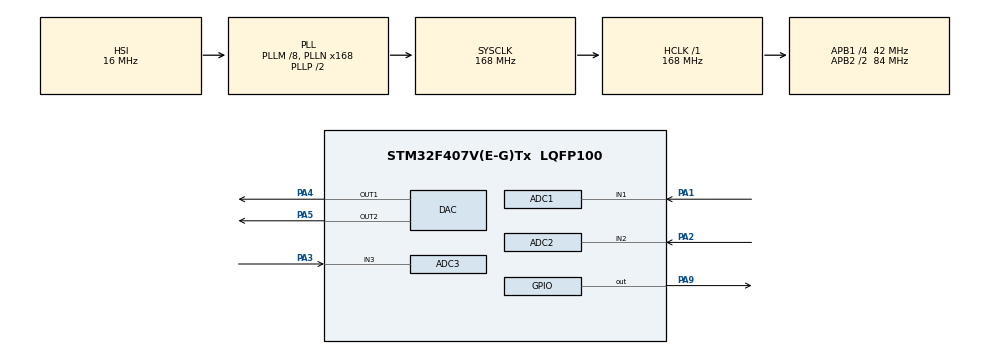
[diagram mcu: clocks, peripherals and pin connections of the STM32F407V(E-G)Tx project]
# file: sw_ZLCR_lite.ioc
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ADC1.AutoInjectedConv=DISABLE
ADC1.Channel-0\#ChannelRegularConversion=ADC_CHANNEL_1
ADC1.ClockPrescaler=ADC_CLOCK_SYNC_PCLK_DIV4
ADC1.ContinuousConvMode=DISABLE
ADC1.DMAAccessMode=ADC_DMAACCESSMODE_1
ADC1.DMAContinuousRequests=ENABLE
ADC1.DataAlign=ADC_DATAALIGN_RIGHT
ADC1.DiscontinuousConvMode=DISABLE
ADC1.EOCSelection=ADC_EOC_SEQ_CONV
ADC1.EnableAnalogWatchDog=false
ADC1.ExternalTrigConv=ADC_EXTERNALTRIGCONV_T2_TRGO
ADC1.ExternalTrigConvEdge=ADC_EXTERNALTRIGCONVEDGE_RISING
ADC1.InjNumberOfConversion=0
ADC1.InjectedDiscontinuousConvMode=DISABLE
ADC1.Mode=ADC_TRIPLEMODE_REGSIMULT
ADC1.NbrOfConversion=1
ADC1.NbrOfConversionFlag=1
ADC1.Rank-0\#ChannelRegularConversion=1
ADC1.Resolution=ADC_RESOLUTION_12B
ADC1.SamplingTime-0\#ChannelRegularConversion=ADC_SAMPLETIME_3CYCLES
ADC1.ScanConvMode=DISABLE
ADC1.master=1
ADC2.AutoInjectedConv=DISABLE
ADC2.Channel-0\#ChannelRegularConversion=ADC_CHANNEL_2
ADC2.ClockPrescaler=ADC_CLOCK_SYNC_PCLK_DIV4
ADC2.ContinuousConvMode=DISABLE
ADC2.DMAAccessMode=ADC_DMAACCESSMODE_1
ADC2.DMAContinuousRequests=DISABLE
ADC2.DataAlign=ADC_DATAALIGN_RIGHT
ADC2.DiscontinuousConvMode=DISABLE
ADC2.EOCSelection=ADC_EOC_SINGLE_CONV
ADC2.EnableAnalogWatchDog=false
ADC2.InjectedDiscontinuousConvMode=DISABLE
ADC2.Mode=ADC_TRIPLEMODE_REGSIMULT
ADC2.NbrOfConversion=1
ADC2.NbrOfConversionFlag=1
ADC2.Rank-0\#ChannelRegularConversion=1
ADC2.Resolution=ADC_RESOLUTION_12B
ADC2.SamplingTime-0\#ChannelRegularConversion=ADC_SAMPLETIME_3CYCLES
ADC2.ScanConvMode=DISABLE
ADC3.AutoInjectedConv=DISABLE
ADC3.Channel-0\#ChannelRegularConversion=ADC_CHANNEL_3
ADC3.DMAAccessMode=ADC_DMAACCESSMODE_1
ADC3.InjectedDiscontinuousConvMode=DISABLE
ADC3.Mode=ADC_TRIPLEMODE_REGSIMULT
ADC3.NbrOfConversionFlag=1
ADC3.Rank-0\#ChannelRegularConversion=1
ADC3.SamplingTime-0\#ChannelRegularConversion=ADC_SAMPLETIME_3CYCLES
DAC.DAC_Channel=DAC_CHANNEL_1
DAC.DAC_Channel2=DAC_CHANNEL_2
DAC.DAC_Trigger=DAC_TRIGGER_T2_TRGO
DAC.DAC_Trigger2=DAC_TRIGGER_SOFTWARE
DAC.WaveGeneration=DISABLE
DAC.WaveGeneration2=DISABLE
Dma.ADC1.0.Direction=DMA_PERIPH_TO_MEMORY
Dma.ADC1.0.FIFOMode=DMA_FIFOMODE_DISABLE
Dma.ADC1.0.Instance=DMA2_Stream0
Dma.ADC1.0.MemDataAlignment=DMA_MDATAALIGN_HALFWORD
Dma.ADC1.0.MemInc=DMA_MINC_ENABLE
Dma.ADC1.0.Mode=DMA_CIRCULAR
Dma.ADC1.0.PeriphDataAlignment=DMA_PDATAALIGN_HALFWORD
Dma.ADC1.0.PeriphInc=DMA_PINC_DISABLE
Dma.ADC1.0.Priority=DMA_PRIORITY_LOW
Dma.DAC1.1.Direction=DMA_MEMORY_TO_PERIPH
Dma.DAC1.1.FIFOMode=DMA_FIFOMODE_DISABLE
Dma.DAC1.1.Instance=DMA1_Stream5
Dma.DAC1.1.MemDataAlignment=DMA_MDATAALIGN_HALFWORD
Dma.DAC1.1.MemInc=DMA_MINC_ENABLE
Dma.DAC1.1.Mode=DMA_CIRCULAR
Dma.DAC1.1.PeriphDataAlignment=DMA_PDATAALIGN_HALFWORD
Dma.DAC1.1.PeriphInc=DMA_PINC_DISABLE
Dma.DAC1.1.Priority=DMA_PRIORITY_LOW
Dma.Request0=ADC1
Dma.Request1=DAC1
Mcu.Family=STM32F4
Mcu.Name=STM32F407V(E-G)Tx
Mcu.Package=LQFP100
NVIC.DMA1_Stream5_IRQn=true\:0\:0\:false\:false\:true
NVIC.DMA2_Stream0_IRQn=true\:0\:0\:false\:false\:true
NVIC.PriorityGroup=NVIC_PRIORITYGROUP_4
PA1.Signal=ADCx_IN1
PA13.Mode=Serial_Wire
PA13.Signal=SYS_JTMS-SWDIO
PA14.Mode=Serial_Wire
PA14.Signal=SYS_JTCK-SWCLK
PA2.Signal=ADCx_IN2
PA3.Signal=ADCx_IN3
PA4.Signal=COMP_DAC1_group
PA5.Signal=COMP_DAC2_group
PA9.Signal=GPIO_Output
PH0-OSC_IN.Mode=HSE-External-Clock-Source
PH0-OSC_IN.Signal=RCC_OSC_IN
PH1-OSC_OUT.Mode=HSE-External-Clock-Source
PH1-OSC_OUT.Signal=RCC_OSC_OUT
ProjectManager.HeapSize=0x1000
ProjectManager.StackSize=0x400
ProjectManager.TargetToolchain=MDK-ARM V5
RCC.48MHZClocksFreq_Value=84000000
RCC.AHBCLKDivider=RCC_SYSCLK_DIV1
RCC.AHBFreq_Value=168000000
RCC.APB1CLKDivider=RCC_HCLK_DIV4
RCC.APB1Freq_Value=42000000
RCC.APB1TimFreq_Value=84000000
RCC.APB2CLKDivider=RCC_HCLK_DIV2
RCC.APB2Freq_Value=84000000
RCC.APB2TimFreq_Value=168000000
RCC.ClockTypeHCLK=RCC_CLOCKTYPE_HCLK
RCC.ClockTypePCLK1=RCC_CLOCKTYPE_PCLK1
RCC.ClockTypePCLK2=RCC_CLOCKTYPE_PCLK2
RCC.ClockTypeSysClk=RCC_CLOCKTYPE_SYSCLK
RCC.CortexFreq_Value=168000000
RCC.Cortex_Div=SYSTICK_CLKSOURCE_HCLK
RCC.EnableExtClockForI2S=false
RCC.EnableHSE=true
RCC.EnableHSERTCDevisor=false
RCC.EnableLSE=false
RCC.EnableLSERTC=false
RCC.ExtClockEnable=false
RCC.HCLKFreq_Value=168000000
RCC.HSEState=RCC_HSE_BYPASS
RCC.HSE_VALUE=8000000
RCC.HSIState=RCC_HSI_ON
RCC.HSI_VALUE=16000000
RCC.I2SEnable=false
RCC.IWDGEnable=false
RCC.LSE_VALUE=32768
RCC.LSIState=RCC_LSI_OFF
RCC.MCO1OutPutEnable=false
RCC.MCO2OutPutEnable=false
RCC.OscillatorTypeHSI=RCC_OSCILLATORTYPE_HSI
RCC.PLLM=8
RCC.PLLN=168
RCC.PLLP=RCC_PLLP_DIV2
RCC.PLLSource=RCC_PLLSOURCE_HSI
RCC.PLLSourceVirtual=RCC_PLLSOURCE_HSI
RCC.PLLState=RCC_PLL_ON
RCC.RCC_MCODiv1=RCC_MCODIV_1
RCC.RCC_MCODiv2=RCC_MCODIV_1
RCC.RCC_RTC_Clock_Source_FROM_HSE=RCC_RTCCLKSOURCE_HSE_DIV2
RCC.RNGEnable=false
RCC.RTCEnable=false
RCC.SDIOEnable=false
RCC.SYSCLKFreq_VALUE=168000000
RCC.SYSCLKSource=RCC_SYSCLKSOURCE_PLLCLK
RCC.USBFSEnable=false
RCC.USBHSEnable=false
RCC.VCOOutputFreq_Value=336000000
SH.ADCx_IN1.0=ADC1_IN1,IN1
SH.ADCx_IN2.0=ADC2_IN2,IN2
SH.ADCx_IN3.0=ADC3_IN3,IN3
SH.COMP_DAC1_group.0=DAC_OUT1,DAC_OUT1
SH.COMP_DAC2_group.0=DAC_OUT2,DAC_OUT2
TIM2.Period=1679
TIM2.TIM_MasterOutputTrigger=TIM_TRGO_UPDATE
VP_TIM2_VS_ClockSourceINT.Mode=Internal
board=sw_ZLCR_lite

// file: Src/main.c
/**
  ******************************************************************************
  * File Name          : main.c
  * Description        : Main program body
  ******************************************************************************
  *
  * COPYRIGHT(c) 2017 STMicroelectronics
  *
  * Redistribution and use in source and binary forms, with or without modification,
  * are permitted provided that the following conditions are met:
  *   1. Redistributions of source code must retain the above copyright notice,
  *      this list of conditions and the following disclaimer.
  *   2. Redistributions in binary form must reproduce the above copyright notice,
  *      this list of conditions and the following disclaimer in the documentation
  *      and/or other materials provided with the distribution.
  *   3. Neither the name of STMicroelectronics nor the names of its contributors
  *      may be used to endorse or promote products derived from this software
  *      without specific prior written permission.
  *
  * THIS SOFTWARE IS PROVIDED BY THE COPYRIGHT HOLDERS AND CONTRIBUTORS "AS IS"
  * AND ANY EXPRESS OR IMPLIED WARRANTIES, INCLUDING, BUT NOT LIMITED TO, THE
  * IMPLIED WARRANTIES OF MERCHANTABILITY AND FITNESS FOR A PARTICULAR PURPOSE ARE
  * DISCLAIMED. IN NO EVENT SHALL THE COPYRIGHT HOLDER OR CONTRIBUTORS BE LIABLE
  * FOR ANY DIRECT, INDIRECT, INCIDENTAL, SPECIAL, EXEMPLARY, OR CONSEQUENTIAL
  * DAMAGES (INCLUDING, BUT NOT LIMITED TO, PROCUREMENT OF SUBSTITUTE GOODS OR
  * SERVICES; LOSS OF USE, DATA, OR PROFITS; OR BUSINESS INTERRUPTION) HOWEVER
  * CAUSED AND ON ANY THEORY OF LIABILITY, WHETHER IN CONTRACT, STRICT LIABILITY,
  * OR TORT (INCLUDING NEGLIGENCE OR OTHERWISE) ARISING IN ANY WAY OUT OF THE USE
  * OF THIS SOFTWARE, EVEN IF ADVISED OF THE POSSIBILITY OF SUCH DAMAGE.
  *
  ******************************************************************************
  */
#include "main.h"
#include "stm32f4xx_hal.h"

/* USER CODE BEGIN Includes */
#include "BSP.h"
/* USER CODE END Includes */

ADC_HandleTypeDef hadc1;
ADC_HandleTypeDef hadc2;
ADC_HandleTypeDef hadc3;
DMA_HandleTypeDef hdma_adc1;

DAC_HandleTypeDef hdac;
DMA_HandleTypeDef hdma_dac1;

TIM_HandleTypeDef htim2;

/* USER CODE BEGIN PV */
/* Private variables ---------------------------------------------------------*/

/* USER CODE END PV */

void SystemClock_Config(void);
void Error_Handler(void);
static void MX_GPIO_Init(void);
static void MX_DMA_Init(void);
static void MX_ADC1_Init(void);
static void MX_ADC2_Init(void);
static void MX_ADC3_Init(void);
static void MX_DAC_Init(void);
static void MX_TIM2_Init(void);

/* USER CODE BEGIN PFP */
/* Private function prototypes -----------------------------------------------*/

/* USER CODE END PFP */

/* USER CODE BEGIN 0 */
void HAL_ADC_ConvCpltCallback(ADC_HandleTypeDef* hadc)
{
    HAL_GPIO_TogglePin(GPIOA, GPIO_PIN_9);
}
/* USER CODE END 0 */

int main(void)
{

  /* MCU Configuration----------------------------------------------------------*/

  /* Reset of all peripherals, Initializes the Flash interface and the Systick. */
  HAL_Init();

  /* Configure the system clock */
  SystemClock_Config();

  /* Initialize all configured peripherals */
  MX_GPIO_Init();
  MX_DMA_Init();
  MX_ADC1_Init();
  MX_ADC2_Init();
  MX_ADC3_Init();
  MX_DAC_Init();
  MX_TIM2_Init();

  /* USER CODE BEGIN 2 */
    HAL_DAC_SetValue(&hdac, DAC1_CHANNEL_1, DAC_ALIGN_12B_R, 2047);
    HAL_DAC_Start_DMA(&hdac, DAC1_CHANNEL_1, (uint32_t *)I2S_DACBuf, 100, DAC_ALIGN_12B_R);
    HAL_DAC_Start(&hdac, DAC1_CHANNEL_2);
    HAL_ADCEx_MultiModeStart_DMA(&hadc1, (uint32_t *)&I2S_ADCBuf, 300);
    __HAL_ADC_ENABLE(&hadc1);
    __HAL_ADC_ENABLE(&hadc2);
    __HAL_ADC_ENABLE(&hadc3);
    HAL_TIM_Base_Start(&htim2);
  /* USER CODE END 2 */

  /* Infinite loop */
  while (1)
  {

  }

}

/** System Clock Configuration
*/
void SystemClock_Config(void)
{

  RCC_OscInitTypeDef RCC_OscInitStruct;
  RCC_ClkInitTypeDef RCC_ClkInitStruct;

    /**Configure the main internal regulator output voltage
    */
  __HAL_RCC_PWR_CLK_ENABLE();

  __HAL_PWR_VOLTAGESCALING_CONFIG(PWR_REGULATOR_VOLTAGE_SCALE1);

    /**Initializes the CPU, AHB and APB busses clocks
    */
  RCC_OscInitStruct.OscillatorType = RCC_OSCILLATORTYPE_HSI;
  RCC_OscInitStruct.HSIState = RCC_HSI_ON;
  RCC_OscInitStruct.HSICalibrationValue = 16;
  RCC_OscInitStruct.PLL.PLLState = RCC_PLL_ON;
  RCC_OscInitStruct.PLL.PLLSource = RCC_PLLSOURCE_HSI;
  RCC_OscInitStruct.PLL.PLLM = 8;
  RCC_OscInitStruct.PLL.PLLN = 168;
  RCC_OscInitStruct.PLL.PLLP = RCC_PLLP_DIV2;
  RCC_OscInitStruct.PLL.PLLQ = 4;
  if (HAL_RCC_OscConfig(&RCC_OscInitStruct) != HAL_OK)
  {
    Error_Handler();
  }

    /**Initializes the CPU, AHB and APB busses clocks
    */
  RCC_ClkInitStruct.ClockType = RCC_CLOCKTYPE_HCLK|RCC_CLOCKTYPE_SYSCLK
                              |RCC_CLOCKTYPE_PCLK1|RCC_CLOCKTYPE_PCLK2;
  RCC_ClkInitStruct.SYSCLKSource = RCC_SYSCLKSOURCE_PLLCLK;
  RCC_ClkInitStruct.AHBCLKDivider = RCC_SYSCLK_DIV1;
  RCC_ClkInitStruct.APB1CLKDivider = RCC_HCLK_DIV4;
  RCC_ClkInitStruct.APB2CLKDivider = RCC_HCLK_DIV2;

  if (HAL_RCC_ClockConfig(&RCC_ClkInitStruct, FLASH_LATENCY_5) != HAL_OK)
  {
    Error_Handler();
  }

    /**Configure the Systick interrupt time
    */
  HAL_SYSTICK_Config(HAL_RCC_GetHCLKFreq()/1000);

    /**Configure the Systick
    */
  HAL_SYSTICK_CLKSourceConfig(SYSTICK_CLKSOURCE_HCLK);

  /* SysTick_IRQn interrupt configuration */
  HAL_NVIC_SetPriority(SysTick_IRQn, 0, 0);
}

/* ADC1 init function */
static void MX_ADC1_Init(void)
{

  ADC_MultiModeTypeDef multimode;
  ADC_ChannelConfTypeDef sConfig;

    /**Configure the global features of the ADC (Clock, Resolution, Data Alignment and number of conversion)
    */
  hadc1.Instance = ADC1;
  hadc1.Init.ClockPrescaler = ADC_CLOCK_SYNC_PCLK_DIV4;
  hadc1.Init.Resolution = ADC_RESOLUTION_12B;
  hadc1.Init.ScanConvMode = DISABLE;
  hadc1.Init.ContinuousConvMode = DISABLE;
  hadc1.Init.DiscontinuousConvMode = DISABLE;
  hadc1.Init.ExternalTrigConvEdge = ADC_EXTERNALTRIGCONVEDGE_RISING;
  hadc1.Init.ExternalTrigConv = ADC_EXTERNALTRIGCONV_T2_TRGO;
  hadc1.Init.DataAlign = ADC_DATAALIGN_RIGHT;
  hadc1.Init.NbrOfConversion = 1;
  hadc1.Init.DMAContinuousRequests = ENABLE;
  hadc1.Init.EOCSelection = ADC_EOC_SEQ_CONV;
  if (HAL_ADC_Init(&hadc1) != HAL_OK)
  {
    Error_Handler();
  }

    /**Configure the ADC multi-mode
    */
  multimode.Mode = ADC_TRIPLEMODE_REGSIMULT;
  multimode.DMAAccessMode = ADC_DMAACCESSMODE_1;
  multimode.TwoSamplingDelay = ADC_TWOSAMPLINGDELAY_5CYCLES;
  if (HAL_ADCEx_MultiModeConfigChannel(&hadc1, &multimode) != HAL_OK)
  {
    Error_Handler();
  }

    /**Configure for the selected ADC regular channel its corresponding rank in the sequencer and its sample time.
    */
  sConfig.Channel = ADC_CHANNEL_1;
  sConfig.Rank = 1;
  sConfig.SamplingTime = ADC_SAMPLETIME_3CYCLES;
  if (HAL_ADC_ConfigChannel(&hadc1, &sConfig) != HAL_OK)
  {
    Error_Handler();
  }

}

/* ADC2 init function */
static void MX_ADC2_Init(void)
{

  ADC_ChannelConfTypeDef sConfig;

    /**Configure the global features of the ADC (Clock, Resolution, Data Alignment and number of conversion)
    */
  hadc2.Instance = ADC2;
  hadc2.Init.ClockPrescaler = ADC_CLOCK_SYNC_PCLK_DIV4;
  hadc2.Init.Resolution = ADC_RESOLUTION_12B;
  hadc2.Init.ScanConvMode = DISABLE;
  hadc2.Init.ContinuousConvMode = DISABLE;
  hadc2.Init.DiscontinuousConvMode = DISABLE;
  hadc2.Init.DataAlign = ADC_DATAALIGN_RIGHT;
  hadc2.Init.NbrOfConversion = 1;
  hadc2.Init.DMAContinuousRequests = DISABLE;
  hadc2.Init.EOCSelection = ADC_EOC_SINGLE_CONV;
  if (HAL_ADC_Init(&hadc2) != HAL_OK)
  {
    Error_Handler();
  }

    /**Configure for the selected ADC regular channel its corresponding rank in the sequencer and its sample time.
    */
  sConfig.Channel = ADC_CHANNEL_2;
  sConfig.Rank = 1;
  sConfig.SamplingTime = ADC_SAMPLETIME_3CYCLES;
  if (HAL_ADC_ConfigChannel(&hadc2, &sConfig) != HAL_OK)
  {
    Error_Handler();
  }

}

/* ADC3 init function */
static void MX_ADC3_Init(void)
{

  ADC_ChannelConfTypeDef sConfig;

    /**Configure the global features of the ADC (Clock, Resolution, Data Alignment and number of conversion)
    */
  hadc3.Instance = ADC3;
  hadc3.Init.ClockPrescaler = ADC_CLOCK_SYNC_PCLK_DIV4;
  hadc3.Init.Resolution = ADC_RESOLUTION_12B;
  hadc3.Init.ScanConvMode = DISABLE;
  hadc3.Init.ContinuousConvMode = DISABLE;
  hadc3.Init.DiscontinuousConvMode = DISABLE;
  hadc3.Init.DataAlign = ADC_DATAALIGN_RIGHT;
  hadc3.Init.NbrOfConversion = 1;
  hadc3.Init.DMAContinuousRequests = DISABLE;
  hadc3.Init.EOCSelection = ADC_EOC_SINGLE_CONV;
  if (HAL_ADC_Init(&hadc3) != HAL_OK)
  {
    Error_Handler();
  }

    /**Configure for the selected ADC regular channel its corresponding rank in the sequencer and its sample time.
    */
  sConfig.Channel = ADC_CHANNEL_3;
  sConfig.Rank = 1;
  sConfig.SamplingTime = ADC_SAMPLETIME_3CYCLES;
  if (HAL_ADC_ConfigChannel(&hadc3, &sConfig) != HAL_OK)
  {
    Error_Handler();
  }

}

/* DAC init function */
static void MX_DAC_Init(void)
{

  DAC_ChannelConfTypeDef sConfig;

    /**DAC Initialization
    */
  hdac.Instance = DAC;
  if (HAL_DAC_Init(&hdac) != HAL_OK)
  {
    Error_Handler();
  }

    /**DAC channel OUT1 config
    */
  sConfig.DAC_Trigger = DAC_TRIGGER_T2_TRGO;
  sConfig.DAC_OutputBuffer = DAC_OUTPUTBUFFER_ENABLE;
  if (HAL_DAC_ConfigChannel(&hdac, &sConfig, DAC_CHANNEL_1) != HAL_OK)
  {
    Error_Handler();
  }

    /**DAC channel OUT2 config
    */
  sConfig.DAC_Trigger = DAC_TRIGGER_SOFTWARE;
  if (HAL_DAC_ConfigChannel(&hdac, &sConfig, DAC_CHANNEL_2) != HAL_OK)
  {
    Error_Handler();
  }

}

/* TIM2 init function */
static void MX_TIM2_Init(void)
{

  TIM_ClockConfigTypeDef sClockSourceConfig;
  TIM_MasterConfigTypeDef sMasterConfig;

  htim2.Instance = TIM2;
  htim2.Init.Prescaler = 0;
  htim2.Init.CounterMode = TIM_COUNTERMODE_UP;
  htim2.Init.Period = 1679;
  htim2.Init.ClockDivision = TIM_CLOCKDIVISION_DIV1;
  if (HAL_TIM_Base_Init(&htim2) != HAL_OK)
  {
    Error_Handler();
  }

  sClockSourceConfig.ClockSource = TIM_CLOCKSOURCE_INTERNAL;
  if (HAL_TIM_ConfigClockSource(&htim2, &sClockSourceConfig) != HAL_OK)
  {
    Error_Handler();
  }

  sMasterConfig.MasterOutputTrigger = TIM_TRGO_UPDATE;
  sMasterConfig.MasterSlaveMode = TIM_MASTERSLAVEMODE_DISABLE;
  if (HAL_TIMEx_MasterConfigSynchronization(&htim2, &sMasterConfig) != HAL_OK)
  {
    Error_Handler();
  }

}

static void MX_DMA_Init(void)
{
  /* DMA controller clock enable */
  __HAL_RCC_DMA2_CLK_ENABLE();
  __HAL_RCC_DMA1_CLK_ENABLE();

  /* DMA interrupt init */
  /* DMA1_Stream5_IRQn interrupt configuration */
  HAL_NVIC_SetPriority(DMA1_Stream5_IRQn, 0, 0);
  HAL_NVIC_EnableIRQ(DMA1_Stream5_IRQn);
  /* DMA2_Stream0_IRQn interrupt configuration */
  HAL_NVIC_SetPriority(DMA2_Stream0_IRQn, 0, 0);
  HAL_NVIC_EnableIRQ(DMA2_Stream0_IRQn);

}

/** Configure pins as
        * Analog
        * Input
        * Output
        * EVENT_OUT
        * EXTI
*/
static void MX_GPIO_Init(void)
{

  GPIO_InitTypeDef GPIO_InitStruct;

  /* GPIO Ports Clock Enable */
  __HAL_RCC_GPIOH_CLK_ENABLE();
  __HAL_RCC_GPIOA_CLK_ENABLE();

  /*Configure GPIO pin Output Level */
  HAL_GPIO_WritePin(GPIOA, GPIO_PIN_9, GPIO_PIN_RESET);

  /*Configure GPIO pin : PA9 */
  GPIO_InitStruct.Pin = GPIO_PIN_9;
  GPIO_InitStruct.Mode = GPIO_MODE_OUTPUT_PP;
  GPIO_InitStruct.Pull = GPIO_NOPULL;
  GPIO_InitStruct.Speed = GPIO_SPEED_FREQ_LOW;
  HAL_GPIO_Init(GPIOA, &GPIO_InitStruct);

}

void Error_Handler(void)
{
  while(1)
  {
  }
}

/************************ (C) COPYRIGHT STMicroelectronics *****END OF FILE****/
